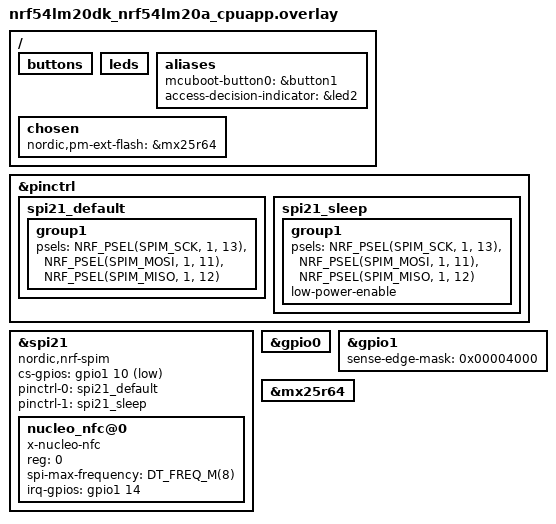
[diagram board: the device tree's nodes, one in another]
/*
 * Copyright (c) 2025 Nordic Semiconductor ASA
 *
 * SPDX-License-Identifier: LicenseRef-Nordic-5-Clause
 */

&pinctrl {
	spi21_default: spi21_default {
		group1 {
			psels = <NRF_PSEL(SPIM_SCK, 1, 13)>,
			        <NRF_PSEL(SPIM_MOSI, 1, 11)>,
			        <NRF_PSEL(SPIM_MISO, 1, 12)>;
		};
	};

	spi21_sleep: spi21_sleep {
		group1 {
			psels = <NRF_PSEL(SPIM_SCK, 1, 13)>,
			        <NRF_PSEL(SPIM_MOSI, 1, 11)>,
			        <NRF_PSEL(SPIM_MISO, 1, 12)>;
			low-power-enable;
		};
	};
};

&spi21 {
	compatible = "nordic,nrf-spim";
	status = "okay";
	cs-gpios = <&gpio1 10 GPIO_ACTIVE_LOW>;

	pinctrl-0 = <&spi21_default>;
	pinctrl-1 = <&spi21_sleep>;
	pinctrl-names = "default", "sleep";
	nucleo_nfc@0 {
		compatible = "x-nucleo-nfc";
		reg = <0>;
		spi-max-frequency = <DT_FREQ_M(8)>;
		irq-gpios = <&gpio1 14 GPIO_ACTIVE_HIGH>;
	};
};

/ {

	/* Disable button0 to align with the nRF54L15DK.
	It also allows to use the button with the same label (1) on all supported dev kits. */
	buttons {
		/delete-node/ button_0;
	};

	leds {
		/delete-node/ led_0;
	};


	aliases {
		/delete-property/ sw0;
		/delete-property/ led0;
		/delete-property/ mcuboot-led0;
		mcuboot-button0 = &button1;
		access-decision-indicator = &led2; /* green LED2 on nRF54LM20DK */
	};

	chosen {
		nordic,pm-ext-flash = &mx25r64;
	};

};

&gpio0 {
	status = "okay";
};

&gpio1 {
	status = "okay";
};

&mx25r64 {
	status = "okay";
};

&gpio1 {
	status = "okay";
	/* Use PORT event rather than GPIOTE IN event, to save power */
	sense-edge-mask = <0x00004000>; /* P1.14 */
};
